# ADuCM355 register map
Vendor: Analog Devices; Series: ADuCM355; File version: 1p0
CPU: CM3 r0p1, little endian, no MPU, no FPU, 3 interrupt priority bits
Registers are 32-bit, read-write, reset 0x0 unless marked. A register's access mark holds for its fields unless they carry their own. Offsets are from the block's base; [hi:lo] are bit positions.

## AFEWDT
Base 0x400C0900
0x00 WDTLD 16-bit reset 0x1000 — Watchdog Timer Load Value
  [15:0] LOAD range 0x00000000..0x0000FFFF — WDT Load Value
0x04 WDTVALS 16-bit reset 0x1000 — Current Count Value
  [15:0] CCOUNT ro — Current WDT Count Value.
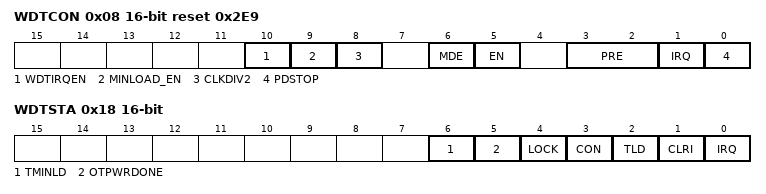
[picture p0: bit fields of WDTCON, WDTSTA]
0x08 WDTCON 16-bit reset 0x2E9 — Watchdog Timer Control Register
  [10] WDTIRQEN — WDT Interrupt Enable
  [9] MINLOAD_EN — Timer Window Control
  [8] CLKDIV2 — Clock Source
  [6] MDE — Timer Mode Select
  [5] EN — Timer Enable
  [3:2] PRE — Prescaler.
  [1] IRQ — WDT Interrupt Enable
    0=Reset (Watchdog Timer timeout creates a reset.); 1=Interrupt (Watchdog Timer timeout creates an interrupt instead of reset.)
  [0] PDSTOP — Power Down Stop Enable
    0=Continue Counting When In Hibernate; 1=Stop Counter When In Hibernate
0x0C WDTCLRI 16-bit — Refresh Watchdog Register
  [15:0] CLRWDG wo range 0x00000000..0x0000FFFF — Refresh Register
0x18 WDTSTA 16-bit — Timer Status
  [6] TMINLD ro — WDTMINLD Write Status
  [5] OTPWRDONE ro — Reset Type Status
  [4] LOCK ro — Lock Status
    0=Open (Timer Operation Not Locked); 1=Locked (Timer Enabled and Locked)
  [3] CON ro — WDTCON Write Status
  [2] TLD ro — WDTVAL Write Status
    0=Sync_Complete (Arm and AFE Watchdog Clock Domains WDTLD values match); 1=Sync_In_Progress (Synchronize In Progress)
  [1] CLRI ro — WDTCLRI Write Status
  [0] IRQ ro — WDT Interrupt
    0=Cleared (Watchdog Timer Interrupt Not Pending); 1=Pending (Watchdog Timer Interrupt Pending)
0x1C WDTMINLD 16-bit reset 0x800 — Minimum Load Value
  [15:0] MIN_LOAD range 0x00000000..0x0000FFFF — WDT Min Load Value

## ALLON — Always On Register
Base 0x400C0A00
0x00 PWRMOD 16-bit reset 0x1 — Power Modes
  [1:0] PWRMOD — Power Mode Control Bits
0x04 PWRKEY 16-bit — Key Protection for PWRMOD
  [15:0] PWRKEY range 0x00000000..0x0000FFFF — PWRMOD Key Register
0x0C OSCKEY 16-bit — Key Protection for OSCCON
  [15:0] OSCKEY range 0x00000000..0x0000FFFF — Oscillator Control Key Register.
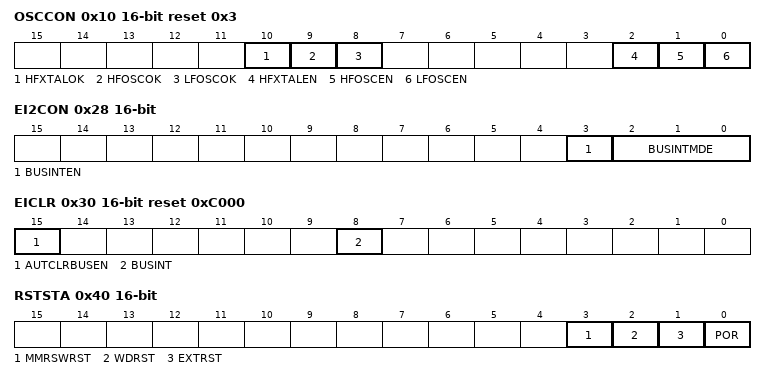
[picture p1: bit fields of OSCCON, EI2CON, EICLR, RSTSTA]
0x10 OSCCON 16-bit reset 0x3 — Oscillator Control
  [10] HFXTALOK ro — Status of HFXTAL Oscillator
  [9] HFOSCOK ro — Status of HFOSC Oscillator
  [8] LFOSCOK ro — Status of LFOSC Oscillator
  [2] HFXTALEN — High Frequency Crystal Oscillator Enable
  [1] HFOSCEN — High Frequency Internal Oscillator Enable
  [0] LFOSCEN — Low Frequency Internal Oscillator Enable
0x28 EI2CON 16-bit — External Interrupt Configuration 2
  [3] BUSINTEN — BUS Interrupt Detection Enable Bit
  [2:0] BUSINTMDE — BUS Interrupt Detection Mode Registers
0x30 EICLR 16-bit reset 0xC000 — External Interrupt Clear
  [15] AUTCLRBUSEN range 0x00000000..0x00000001 — Enable Auto Clear of Bus Interrupt
  [8] BUSINT range 0x00000000..0x00000001 — BUS Interrupt
0x40 RSTSTA 16-bit — Reset Status
  [3] MMRSWRST range 0x00000000..0x00000001 — MMR Software Reset
  [2] WDRST range 0x00000000..0x00000001 — Watchdog Timeout
  [1] EXTRST range 0x00000000..0x00000001 — External Reset
  [0] POR range 0x00000000..0x00000001 — Power-on Reset
0x44 PMUSTA 16-bit — PMU Status
  [2:0] PMUSTATE ro — PMU FSM States
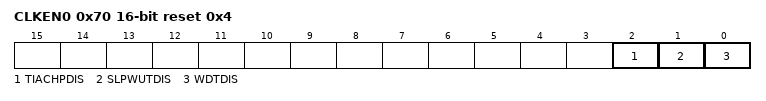
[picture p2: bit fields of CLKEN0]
0x70 CLKEN0 16-bit reset 0x4 — 32KHz Peripheral Clock Enable
  [2] TIACHPDIS — TIA Chop Clock Disable
  [1] SLPWUTDIS — Sleep/Wakeup Timer Clock Disable
  [0] WDTDIS — Watch Dog Timer Clock Disable

## AGPT0 — General Purpose Timer
Base 0x400C0D00
0x00 LD0 16-bit — 16-bit Load Value Register.
  [15:0] LOAD range 0x00000000..0x0000FFFF — Load Value
0x04 VAL0 16-bit — 16-Bit Timer Value Register.
  [15:0] VAL ro — Current Count
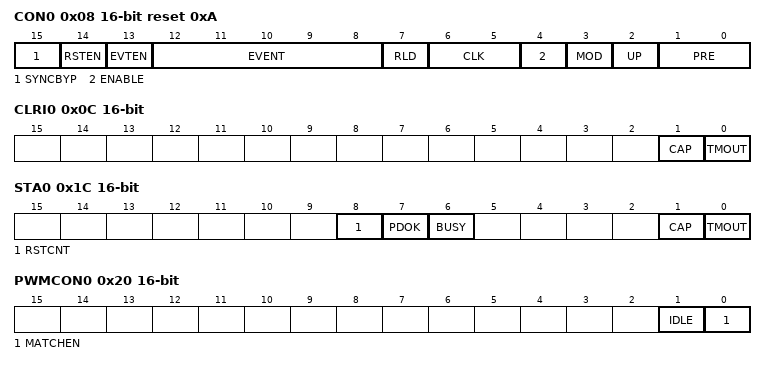
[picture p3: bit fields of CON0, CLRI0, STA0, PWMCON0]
0x08 CON0 16-bit reset 0xA — Control Register.
  [15] SYNCBYP range 0x00000000..0x00000001 — Synchronization Bypass
  [14] RSTEN range 0x00000000..0x00000001 — Counter and Prescale Reset Enable
  [13] EVTEN — Event Select
  [12:8] EVENT range 0x00000000..0x0000001F — Event Select Range
  [7] RLD — Reload Control
  [6:5] CLK — Clock Select
  [4] ENABLE — Timer Enable
  [3] MOD — Timer Mode
  [2] UP — Count up
  [1:0] PRE — Prescaler
0x0C CLRI0 16-bit — Clear Interrupt Register.
  [1] CAP wo — Clear Captured Event Interrupt
  [0] TMOUT wo — Clear Timeout Interrupt
0x10 CAP0 16-bit — Capture Register.
  [15:0] CAP ro — 16-bit Captured Value
0x14 ALD0 16-bit — 16-Bit Load Value, Asynchronous.
  [15:0] ALOAD range 0x00000000..0x0000FFFF — Load Value, Asynchronous
0x18 AVAL0 16-bit — 16-Bit Timer Value, Asynchronous Register.
  [15:0] AVAL ro — Counter Value
0x1C STA0 16-bit — Status Register.
  [8] RSTCNT ro — Counter Reset Occurring
  [7] PDOK ro — Clear Interrupt Register Synchronization
  [6] BUSY ro — Timer Busy
  [1] CAP ro — Capture Event Pending
  [0] TMOUT ro — Timeout Event Occurred
0x20 PWMCON0 16-bit — PWM Control Register.
  [1] IDLE range 0x00000000..0x00000001 — PWM Idle State
  [0] MATCHEN — PWM Match Enabled
0x24 PWMMAT0 16-bit — PWM Match Value Register.
  [15:0] MATCHVAL range 0x00000000..0x0000FFFF — PWM Match Value
0x28 INTEN 16-bit — Interrupt Enable
  [0] INTEN range 0x00000000..0x00000001

## AGPT1 — General Purpose Timer
Base 0x400C0E00
0x00 LD1 16-bit — 16-bit Load Value Register
  [15:0] LOAD range 0x00000000..0x0000FFFF — Load Value
0x04 VAL1 16-bit — 16-bit Timer Value Register
  [15:0] VAL ro — Current Count
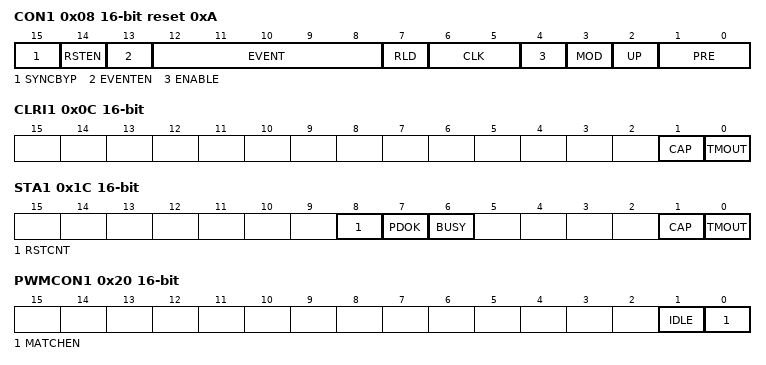
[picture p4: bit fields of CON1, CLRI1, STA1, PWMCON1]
0x08 CON1 16-bit reset 0xA — Control Register
  [15] SYNCBYP range 0x00000000..0x00000001 — Synchronization Bypass
  [14] RSTEN range 0x00000000..0x00000001 — Counter and Prescale Reset Enable
  [13] EVENTEN — Event Select
  [12:8] EVENT range 0x00000000..0x0000001F — Event Select Range
  [7] RLD — Reload Control
  [6:5] CLK — Clock Select
  [4] ENABLE — Timer Enable
  [3] MOD — Timer Mode
  [2] UP — Count up
  [1:0] PRE — Prescaler
0x0C CLRI1 16-bit — Clear Interrupt Register
  [1] CAP wo — Clear Captured Event Interrupt
  [0] TMOUT wo — Clear Timeout Interrupt
0x10 CAP1 16-bit — Capture Register
  [15:0] CAP ro — 16-bit Captured Value.
0x14 ALD1 16-bit — 16-bit Load Value, Asynchronous Register
  [15:0] ALOAD range 0x00000000..0x0000FFFF — Load Value, Asynchronous
0x18 AVAL1 16-bit — 16-bit Timer Value, Asynchronous Register
  [15:0] AVAL ro — Counter Value
0x1C STA1 16-bit — Status Register
  [8] RSTCNT ro — Counter Reset Occurring
  [7] PDOK ro — Clear Interrupt Register Synchronization
  [6] BUSY ro — Timer Busy
  [1] CAP ro — Capture Event Pending
  [0] TMOUT ro — Timeout Event Occurred
0x20 PWMCON1 16-bit — PWM Control Register
  [1] IDLE — PWM Idle State.
  [0] MATCHEN — PWM Match Enabled.
0x24 PWMMAT1 16-bit — PWM Match Value Register
  [15:0] MATCHVAL range 0x00000000..0x0000FFFF — PWM Match Value
0x28 INTEN1 16-bit — Interrupt Enable
  [0] INTEN range 0x00000000..0x00000001

## AFECRC — CRC Accelerator
Base 0x400C1000
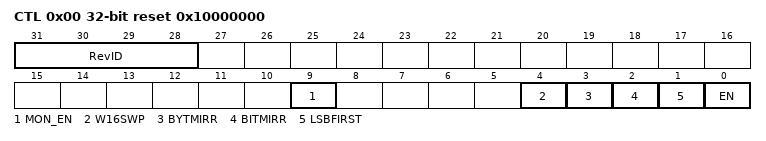
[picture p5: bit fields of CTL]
0x00 CTL reset 0x10000000 — CRC Control Register
  [31:28] RevID ro — Revision ID
  [9] MON_EN — Enable Apb32/Apb16 to Get Address/Data for CRC Calculation
  [4] W16SWP — Word16 Swap Enabled.
  [3] BYTMIRR — Byte Mirroring.
  [2] BITMIRR — Bit Mirroring.
  [1] LSBFIRST — LSB First Calculation Order
  [0] EN — CRC Peripheral Enable
0x04 IPDATA — Data Input.
  [31:0] VALUE wo range 0x00000000..0xFFFFFFFF
0x08 RESULT — CRC Residue
  [31:0] VALUE range 0x00000000..0xFFFFFFFF
0x0C POLY reset 0x4C11DB7 — CRC Reduction Polynomial
  [31:0] VALUE range 0x00000000..0xFFFFFFFF
0x10 IPBITS 8-bit — Input Data Bits
  [7:0] DATA_BITS wo range 0x00000000..0x000000FF — Input Data Bits.
0x14 IPBYTE 8-bit — Input Data Byte
  [7:0] DATA_BYTE wo range 0x00000000..0x000000FF — Input Data Byte.
0x20 CRC_SIG_COMP — CRC Signature Compare Data Input.
  [31:0] CRC_SIG range 0x00000000..0xFFFFFFFF
0x24 CRCINTEN — CRC Error Interrupt Enable Bit
  [0] CRC_ERR_EN
0x28 INTSTA — CRC Error Interrupt Status Bit
  [0] CRC_ERR_ST
